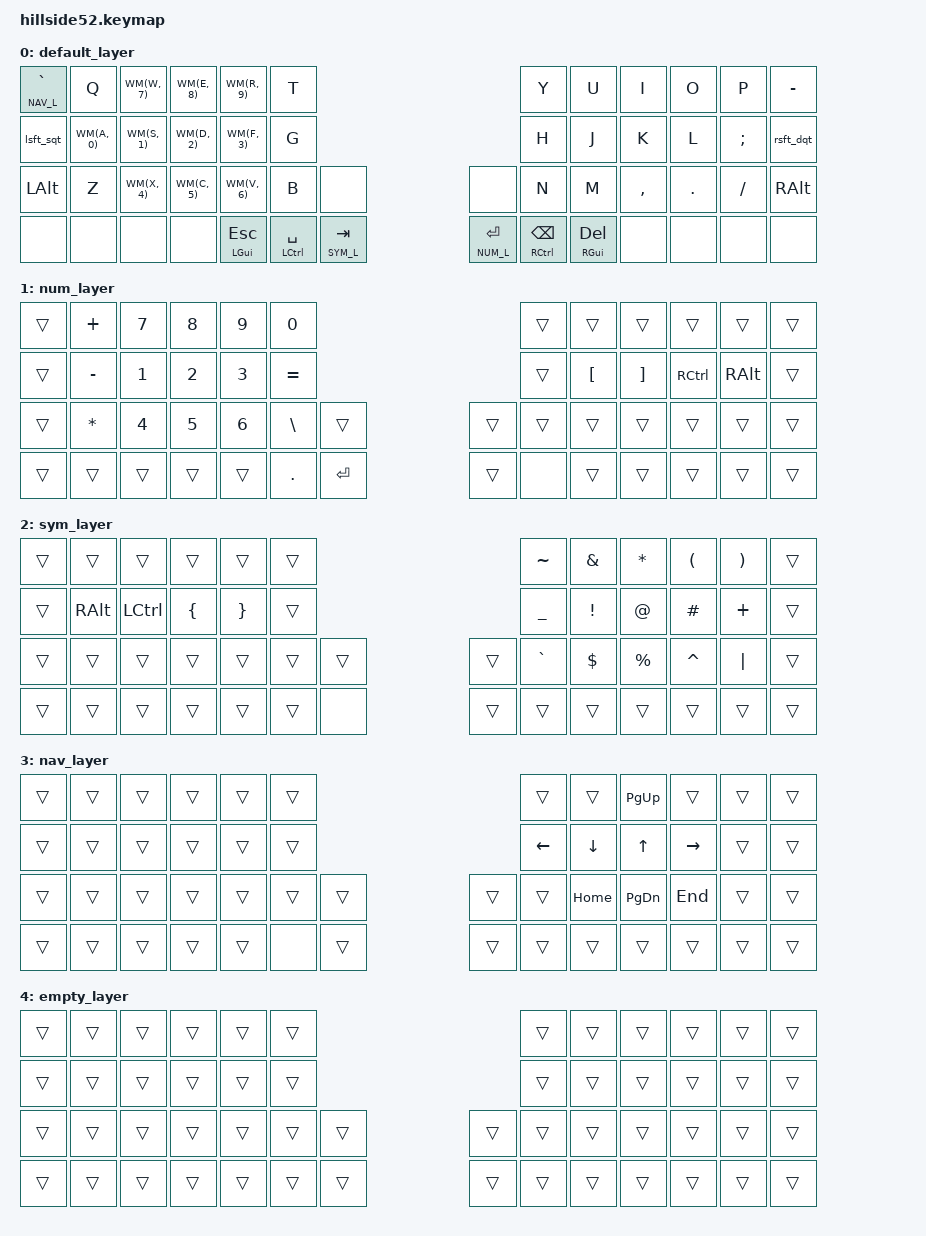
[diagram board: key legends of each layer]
/*
 * Copyright (c) 2021-2022 The ZMK Contributors
 *
 * SPDX-License-Identifier: MIT
 *
 * TODO:
 *  - replace enter and esc keys on thumbs
 */

#include <behaviors.dtsi>
#include <dt-bindings/zmk/bt.h>
#include <dt-bindings/zmk/ext_power.h>
#include <dt-bindings/zmk/keys.h>
#include <dt-bindings/zmk/outputs.h>

#define QWERTY_L     0
#define NUM_L        1
#define SYM_L        2
#define NAV_L        3
#define EMP_L        4

#define XXX        &none
#define ____NA____ &none
#define VVV        &trans

#define Undo   LC(Z)
#define Cut    LC(X)
#define Copy   LC(C)
#define Paste  LC(V)
#define Redo   LC(Y)

#define LGUI_ESC    &kp_fast_hold LGUI  ESC
#define LCTRL_SPACE &kp_slow_hold LCTRL SPACE
#define SYM_TAB     &mo_fast_hold SYM_L TAB
#define NUM_ENTER   &mo_fast_hold NUM_L ENTER
#define RCTRL_BSPC  &kp_fast_hold RCTRL BSPC
#define RGUI_DEL    &kp_fast_hold RGUI  DELETE
#define NAV_GRAVE   &mo_slow_hold NAV_L GRAVE

#define WM(key, num) &wm_##key##_##num
#define WIN_MORPH_MACRO(key, num) \
        wm_##key##_##num: wm_##key##_##num { \
                label = ZMK_MACRO_STRINGIFY(wm_##key##_##num); \
                compatible = "zmk,behavior-mod-morph"; \
                #binding-cells = <0>; \
                bindings = <&kp key>, <&kp N##num>; \
                mods = <(MOD_LGUI)>; \
                keep-mods = <(MOD_LGUI)>; \
        }

/ {
        macros {
                WIN_MORPH_MACRO(A, 0);
                WIN_MORPH_MACRO(S, 1);
                WIN_MORPH_MACRO(D, 2);
                WIN_MORPH_MACRO(F, 3);
                WIN_MORPH_MACRO(X, 4);
                WIN_MORPH_MACRO(C, 5);
                WIN_MORPH_MACRO(V, 6);
                WIN_MORPH_MACRO(W, 7);
                WIN_MORPH_MACRO(E, 8);
                WIN_MORPH_MACRO(R, 9);

                lsft_sqt: lsft_sqt {
                        label = "lsft_sqt";
                        compatible = "zmk,behavior-mod-morph";
                        #binding-cells = <0>;
                        bindings = <&kp LSFT>, <&kp SQT>;
                        mods = <(MOD_RSFT)>;
                };

                rsft_dqt: rsft_dqt {
                        label = "rsft_sqt";
                        compatible = "zmk,behavior-mod-morph";
                        #binding-cells = <0>;
                        bindings = <&kp RSFT>, <&kp DQT>;
                        mods = <(MOD_LSFT)>;
                };        
                
                grave_tilde: grave_tilde {
                        label = "grave_tilde";
                        compatible = "zmk,behavior-mod-morph";
                        #binding-cells = <0>;
                        bindings = <&kp GRAVE>, <&kp TILDE>;
                        mods = <(MOD_RSFT)>;
                };

                /* Similar to mo_fast_hold but pairs with CTRL/SHIFTS like keys
                   instead of layers */
                kp_fast_hold: kp_fast_hold {
                        label = "kp_fast_hold";
                        compatible = "zmk,behavior-hold-tap";
                        #binding-cells = <2>;
                        quick-tap-ms = <200>;       
                        flavor = "hold-preferred";
                        tapping-term-ms = <200>;
                        bindings = <&kp>, <&kp>;
                };

                /*  Assuming slow key, rolling will hold.  If you want the key
                    press you will release it assertively before next press.
                    This is good for ESC/TAB/ENTER key, with fast layers. */
                mo_fast_hold: mo_fast_hold {
                        label = "mo_fast_hold";
                        compatible = "zmk,behavior-hold-tap";
                        #binding-cells = <2>;
                        quick-tap-ms = <200>;       
                        flavor = "hold-preferred";
                        tapping-term-ms = <200>;
                        bindings = <&mo>, <&kp>;
                };

                /* Similar to kp_slow_hold but pairs with Layers instead keys */
                mo_slow_hold: mo_slow_hold {
                        label = "mo_slow_hold";
                        compatible = "zmk,behavior-hold-tap";
                        #binding-cells = <2>;
                        quick-tap-ms = <200>;       
                        flavor = "tap-preferred";
                        tapping-term-ms = <250>;
                        bindings = <&mo>, <&kp>;
                };

                /*  Assuming a fast key, rolling taps. If you want hold you will
                    be explicit. This is good for SPACE bar which will roll 
                    a lot. But not good to pair with a layer */
                kp_slow_hold: kp_slow_hold {
                        label = "kp_slow_hold";
                        compatible = "zmk,behavior-hold-tap";
                        #binding-cells = <2>;
                        quick-tap-ms = <200>;       
                        flavor = "tap-preferred";
                        tapping-term-ms = <250>;
                        bindings = <&kp>, <&kp>;
                };
                
        };

        keymap {
                compatible = "zmk,keymap";

                default_layer {
                        bindings = <
NAV_GRAVE     &kp  Q        WM(W, 7)      WM(E, 8)      WM(R, 9)      &kp  T                                                                                            &kp  Y            &kp  U        &kp  I        &kp  O        &kp  P        &kp  MINUS
&lsft_sqt     WM(A, 0)      WM(S, 1)      WM(D, 2)      WM(F, 3)      &kp  G                                                                                            &kp  H            &kp  J        &kp  K        &kp  L        &kp  SEMI     &rsft_dqt
&kp  LALT     &kp  Z        WM(X, 4)      WM(C, 5)      WM(V, 6)      &kp  B             XXX                                                         XXX                &kp  N            &kp  M        &kp  COMMA    &kp  DOT      &kp  FSLH     &kp  RALT
XXX           XXX           XXX                         XXX           LGUI_ESC           LCTRL_SPACE         SYM_TAB               NUM_ENTER         RCTRL_BSPC         RGUI_DEL          XXX                         XXX           XXX           XXX       
                        >;
                        sensor-bindings = <&inc_dec_kp C_VOL_UP C_VOL_DN &inc_dec_kp PG_UP PG_DN>;      
                };

                num_layer {
                        bindings = <
VVV           &kp  PLUS     &kp  N7       &kp  N8       &kp  N9       &kp  N0                                                                                           VVV               VVV           VVV           VVV           VVV           VVV       
VVV           &kp  MINUS    &kp  N1       &kp  N2       &kp  N3       &kp  EQUAL                                                                                        VVV               &kp  LBKT     &kp  RBKT     &kp  RCTRL    &kp  RALT     VVV       
VVV           &kp  ASTRK    &kp  N4       &kp  N5       &kp  N6       &kp  BSLH          VVV                                                         VVV                VVV               VVV           VVV           VVV           VVV           VVV       
VVV           VVV           VVV                         VVV           VVV                &kp  DOT            &kp  ENTER            VVV               ____NA____         VVV               VVV                         VVV           VVV           VVV       
                        >;
			
                        sensor-bindings = <&inc_dec_kp C_VOL_UP C_VOL_DN &inc_dec_kp PG_UP PG_DN>;
                };

                sym_layer {
                        bindings = <
VVV           VVV           VVV           VVV           VVV           VVV                                                                                               &kp  TILDE        &kp  AMPS     &kp  ASTRK    &kp  LPAR     &kp  RPAR     VVV       
VVV           &kp  RALT     &kp  LCTRL    &kp  LBRC     &kp  RBRC     VVV                                                                                               &kp  UNDER        &kp  EXCL     &kp  AT       &kp  POUND    &kp  PLUS     VVV       
VVV           VVV           VVV           VVV           VVV           VVV                VVV                                                         VVV                &kp  GRAVE        &kp  DOLLAR   &kp  PERCENT  &kp  CARET    &kp  PIPE     VVV       
VVV           VVV           VVV                         VVV           VVV                VVV                 ____NA____            VVV               VVV                VVV               VVV                         VVV           VVV           VVV       
                        >;
			
                        sensor-bindings = <&inc_dec_kp C_VOL_UP C_VOL_DN &inc_dec_kp PG_UP PG_DN>;      
                };

               nav_layer {
                        bindings = <
VVV           VVV           VVV           VVV           VVV           VVV                                                                                               VVV               VVV           &kp PG_UP     VVV           VVV           VVV       
VVV           VVV           VVV           VVV           VVV           VVV                                                                                               &kp LEFT          &kp DOWN      &kp UP        &kp RIGHT     VVV           VVV       
VVV           VVV           VVV           VVV           VVV           VVV                VVV                                                         VVV                VVV               &kp HOME      &kp PG_DN     &kp END       VVV           VVV       
VVV           VVV           VVV                         VVV           VVV                ____NA____          VVV                   VVV               VVV                VVV               VVV                         VVV           VVV           VVV       
                        >;
			
                        sensor-bindings = <&inc_dec_kp C_VOL_UP C_VOL_DN &inc_dec_kp PG_UP PG_DN>;      
                };

                empty_layer {
                        bindings = <
VVV           VVV           VVV           VVV           VVV           VVV                                                                                               VVV               VVV           VVV           VVV           VVV           VVV       
VVV           VVV           VVV           VVV           VVV           VVV                                                                                               VVV               VVV           VVV           VVV           VVV           VVV       
VVV           VVV           VVV           VVV           VVV           VVV                VVV                                                         VVV                VVV               VVV           VVV           VVV           VVV           VVV       
VVV           VVV           VVV                         VVV           VVV                VVV                 VVV                   VVV               VVV                VVV               VVV                         VVV           VVV           VVV       
                        >;
			
                        sensor-bindings = <&inc_dec_kp C_VOL_UP C_VOL_DN &inc_dec_kp PG_UP PG_DN>;
                };
        };
};
